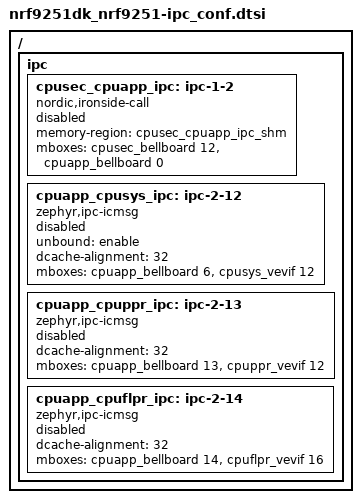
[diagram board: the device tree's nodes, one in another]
/*
 * Copyright (c) 2026 Nordic Semiconductor ASA
 *
 * SPDX-License-Identifier: LicenseRef-Nordic-5-Clause
 */

/ {
	ipc {
		cpusec_cpuapp_ipc: ipc-1-2 {
			compatible = "nordic,ironside-call";
			memory-region = <&cpusec_cpuapp_ipc_shm>;
			mboxes = <&cpusec_bellboard 12>,
				 <&cpuapp_bellboard 0>;
			status = "disabled";
		};

		cpuapp_cpusys_ipc: ipc-2-12 {
			compatible = "zephyr,ipc-icmsg";
			unbound = "enable";
			dcache-alignment = <32>;
			mboxes = <&cpuapp_bellboard 6>,
				 <&cpusys_vevif 12>;
			status = "disabled";
		};

		cpuapp_cpuppr_ipc: ipc-2-13 {
			compatible = "zephyr,ipc-icmsg";
			status = "disabled";
			dcache-alignment = <32>;
			mboxes = <&cpuapp_bellboard 13>,
				 <&cpuppr_vevif 12>;
		};

		cpuapp_cpuflpr_ipc: ipc-2-14 {
			compatible = "zephyr,ipc-icmsg";
			status = "disabled";
			dcache-alignment = <32>;
			mboxes = <&cpuapp_bellboard 14>,
				 <&cpuflpr_vevif 16>;
		};
	};
};
